# AIR32F103xx register map
File version: 1.3
Registers are 32-bit, read-write, reset 0x0 unless marked. A register's access mark holds for its fields unless they carry their own. Offsets are from the block's base; [hi:lo] are bit positions; {n}, {i} and the like mark numbered series.

## DBG — Debug support
Base 0xE0042000
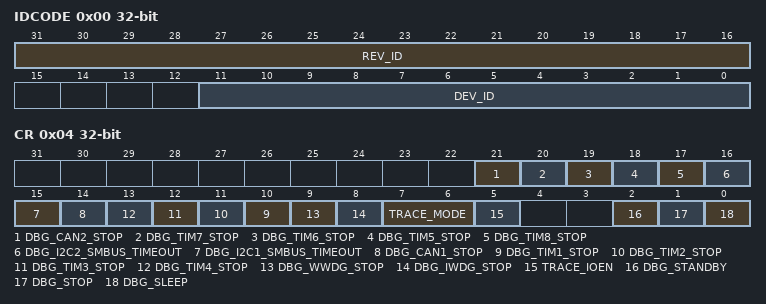
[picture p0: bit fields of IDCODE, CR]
0x00 IDCODE ro — DBGMCU_IDCODE
  [31:16] REV_ID, [11:0] DEV_ID
0x04 CR — DBGMCU_CR
  [21] DBG_CAN2_STOP, [20] DBG_TIM7_STOP, [19] DBG_TIM6_STOP, [18] DBG_TIM5_STOP, [17] DBG_TIM8_STOP, [16] DBG_I2C2_SMBUS_TIMEOUT, [15] DBG_I2C1_SMBUS_TIMEOUT, [14] DBG_CAN1_STOP, [n+9] DBG_TIM{n}_STOP (n=1..4), [9] DBG_WWDG_STOP, [8] DBG_IWDG_STOP, [7:6] TRACE_MODE, [5] TRACE_IOEN, [2] DBG_STANDBY, [1] DBG_STOP, [0] DBG_SLEEP

## UART4 — Universal asynchronous receiver transmitter
Base 0x40004C00
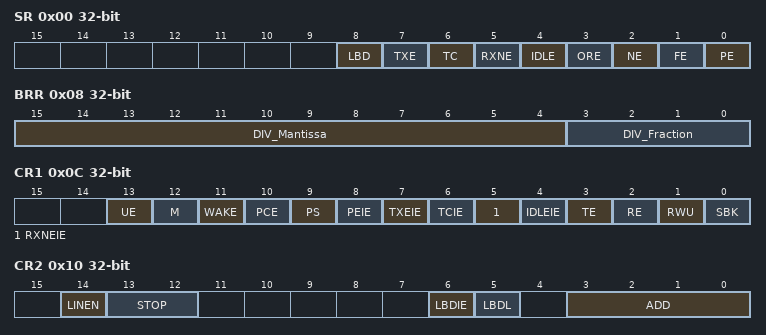
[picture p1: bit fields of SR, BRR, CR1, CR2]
0x00 SR access per field — UART4_SR
  [8] LBD rw — LIN break detection flag
  [7] TXE ro — Transmit data register empty
  [6] TC rw — Transmission complete
  [5] RXNE rw — Read data register not empty
  [4] IDLE ro — IDLE line detected
  [3] ORE ro — Overrun error
  [2] NE ro — Noise error flag
  [1] FE ro — Framing error
  [0] PE ro — Parity error
0x04 DR — UART4_DR
  [8:0] DR
0x08 BRR — UART4_BRR
  [15:4] DIV_Mantissa, [3:0] DIV_Fraction
0x0C CR1 — UART4_CR1
  [13] UE — USART enable
  [12] M — Word length
  [11] WAKE — Wakeup method
  [10] PCE — Parity control enable
  [9] PS — Parity selection
  [8] PEIE — PE interrupt enable
  [7] TXEIE — TXE interrupt enable
  [6] TCIE — Transmission complete interrupt enable
  [5] RXNEIE — RXNE interrupt enable
  [4] IDLEIE — IDLE interrupt enable
  [3] TE — Transmitter enable
  [2] RE — Receiver enable
  [1] RWU — Receiver wakeup
  [0] SBK — Send break
0x10 CR2 — UART4_CR2
  [14] LINEN — LIN mode enable
  [13:12] STOP — STOP bits
  [6] LBDIE — LIN break detection interrupt enable
  [5] LBDL — lin break detection length
  [3:0] ADD — Address of the USART node
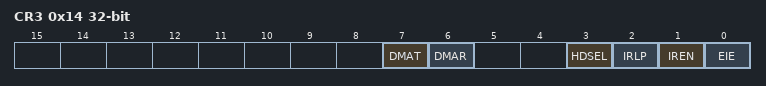
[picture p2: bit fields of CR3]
0x14 CR3 — UART4_CR3
  [7] DMAT — DMA enable transmitter
  [6] DMAR — DMA enable receiver
  [3] HDSEL — Half-duplex selection
  [2] IRLP — IrDA low-power
  [1] IREN — IrDA mode enable
  [0] EIE — Error interrupt enable

## UART5 — Universal asynchronous receiver transmitter
Base 0x40005000
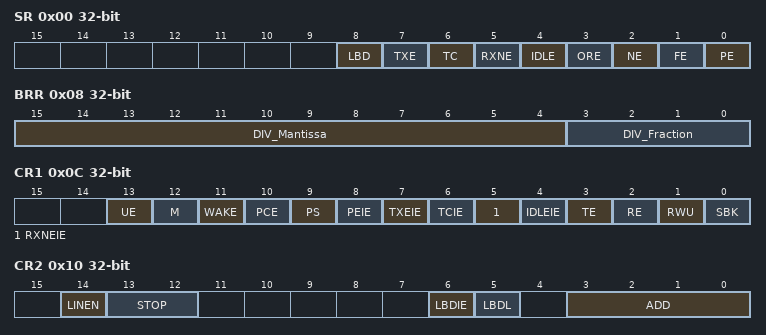
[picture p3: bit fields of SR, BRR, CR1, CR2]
0x00 SR access per field — UART4_SR
  [8] LBD rw, [7] TXE ro, [6] TC rw, [5] RXNE rw, [4] IDLE ro, [3] ORE ro, [2] NE ro, [1] FE ro, [0] PE ro
0x04 DR — UART4_DR
  [8:0] DR
0x08 BRR — UART4_BRR
  [15:4] DIV_Mantissa, [3:0] DIV_Fraction
0x0C CR1 — UART4_CR1
  [13] UE, [12] M, [11] WAKE, [10] PCE, [9] PS, [8] PEIE, [7] TXEIE, [6] TCIE, [5] RXNEIE, [4] IDLEIE, [3] TE, [2] RE, [1] RWU, [0] SBK
0x10 CR2 — UART4_CR2
  [14] LINEN, [13:12] STOP, [6] LBDIE, [5] LBDL, [3:0] ADD
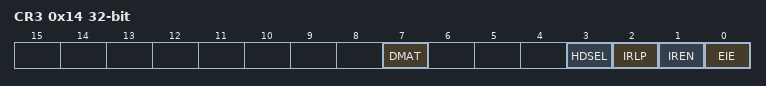
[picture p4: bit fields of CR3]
0x14 CR3 — UART4_CR3
  [7] DMAT — DMA enable transmitter
  [3] HDSEL — Half-duplex selection
  [2] IRLP — IrDA low-power
  [1] IREN — IrDA mode enable
  [0] EIE — Error interrupt enable

## CRC — CRC calculation unit
Base 0x40023000
0x00 DR reset 0xFFFFFFFF — Data register
  [31:0] DR — Data Register
0x04 IDR — Independent Data register
  [7:0] IDR
0x08 CR wo — Control register
  [0] RESET — Reset bit

## FLASH
Base 0x40022000
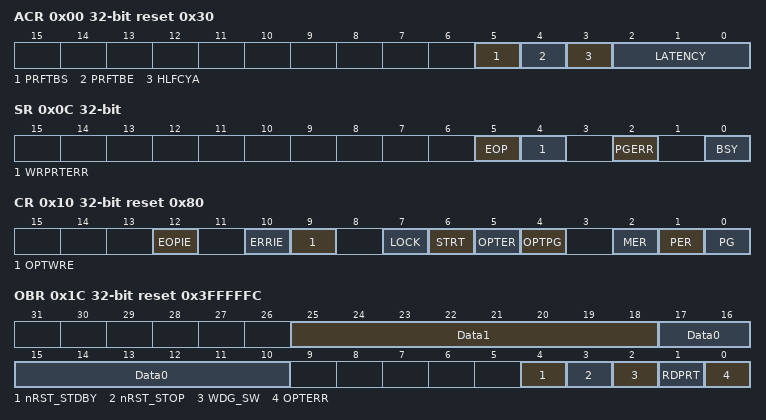
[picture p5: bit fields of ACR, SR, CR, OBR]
0x00 ACR access per field reset 0x30 — Flash access control register
  [5] PRFTBS ro — Prefetch buffer status
  [4] PRFTBE rw — Prefetch buffer enable
  [3] HLFCYA rw — Flash half cycle access enable
  [2:0] LATENCY rw
0x04 KEYR wo — Flash key register
  [31:0] KEY — FPEC key
0x08 OPTKEYR wo — Flash option key register
  [31:0] OPTKEY — Option byte key
0x0C SR access per field — Status register
  [5] EOP rw — End of operation
  [4] WRPRTERR rw — Write protection error
  [2] PGERR rw — Programming error
  [0] BSY ro — Busy
0x10 CR reset 0x80 — Control register
  [12] EOPIE — End of operation interrupt enable
  [10] ERRIE — Error interrupt enable
  [9] OPTWRE — Option bytes write enable
  [7] LOCK
  [6] STRT — Start
  [5] OPTER — Option byte erase
  [4] OPTPG — Option byte programming
  [2] MER — Mass Erase
  [1] PER — Page Erase
  [0] PG — Programming
0x14 AR wo — Flash address register
  [31:0] FAR — Flash Address
0x1C OBR ro reset 0x3FFFFFC — Option byte register
  [25:18] Data1
  [17:10] Data0
  [4] nRST_STDBY
  [3] nRST_STOP
  [2] WDG_SW
  [1] RDPRT — Read protection
  [0] OPTERR — Option byte error
0x20 WRPR ro reset 0xFFFFFFFF — Write protection register
  [31:0] WRP — Write protect

## NVIC — Nested Vectored Interrupt Controller
Base 0xE000E000
0x04 ICTR ro — Interrupt Controller Type Register
  [3:0] INTLINESNUM — Total number of interrupt lines in groups
0x100 ISER0 — Interrupt Set-Enable Register
  [31:0] SETENA
0x104 ISER1 — Interrupt Set-Enable Register
  [31:0] SETENA
0x180 ICER0 — Interrupt Clear-Enable Register
  [31:0] CLRENA
0x184 ICER1 — Interrupt Clear-Enable Register
  [31:0] CLRENA
0x200 ISPR0 — Interrupt Set-Pending Register
  [31:0] SETPEND
0x204 ISPR1 — Interrupt Set-Pending Register
  [31:0] SETPEND
0x280 ICPR0 — Interrupt Clear-Pending Register
  [31:0] CLRPEND
0x284 ICPR1 — Interrupt Clear-Pending Register
  [31:0] CLRPEND
0x300 IABR0 ro — Interrupt Active Bit Register
  [31:0] ACTIVE
0x304 IABR1 ro — Interrupt Active Bit Register
  [31:0] ACTIVE
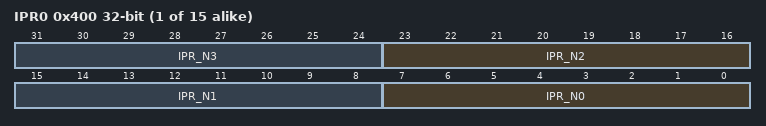
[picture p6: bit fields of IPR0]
{0x400+4i} IPR{i} (i=0..14) — Interrupt Priority Register
  [8n+7:8n] IPR_N{n} (n=0..3)
0xF00 STIR wo — Software Triggered Interrupt Register
  [8:0] INTID — interrupt to be triggered

## USB — Universal serial bus full-speed device interface
Base 0x40005C00
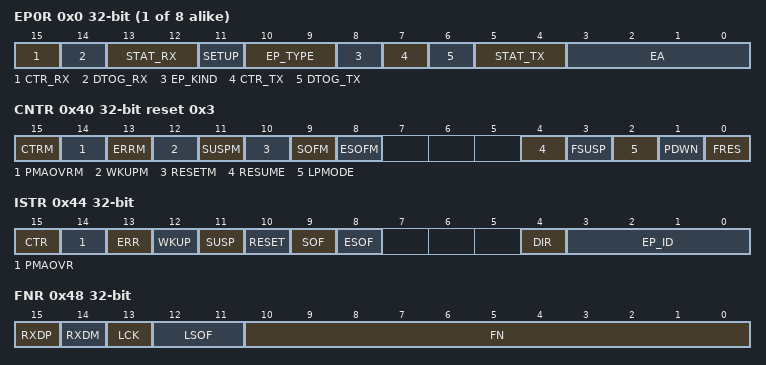
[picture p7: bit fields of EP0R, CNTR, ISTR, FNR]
{0x0+4i} EP{i}R (i=0..7) — endpoint {i} register
  [15] CTR_RX — Correct transfer for reception
  [14] DTOG_RX — Data Toggle, for reception transfers
  [13:12] STAT_RX — Status bits, for reception transfers
  [11] SETUP — Setup transaction completed
  [10:9] EP_TYPE — Endpoint type
  [8] EP_KIND — Endpoint kind
  [7] CTR_TX — Correct Transfer for transmission
  [6] DTOG_TX — Data Toggle, for transmission transfers
  [5:4] STAT_TX — Status bits, for transmission transfers
  [3:0] EA — Endpoint address
0x40 CNTR reset 0x3 — control register
  [15] CTRM — Correct transfer interrupt mask
  [14] PMAOVRM — Packet memory area over / underrun interrupt mask
  [13] ERRM — Error interrupt mask
  [12] WKUPM — Wakeup interrupt mask
  [11] SUSPM — Suspend mode interrupt mask
  [10] RESETM — USB reset interrupt mask
  [9] SOFM — Start of frame interrupt mask
  [8] ESOFM — Expected start of frame interrupt mask
  [4] RESUME — Resume request
  [3] FSUSP — Force suspend
  [2] LPMODE — Low-power mode
  [1] PDWN — Power down
  [0] FRES — Force USB Reset
0x44 ISTR — interrupt status register
  [15] CTR — Correct transfer
  [14] PMAOVR — Packet memory area over / underrun
  [13] ERR — Error
  [12] WKUP — Wakeup
  [11] SUSP — Suspend mode request
  [10] RESET — reset request
  [9] SOF — start of frame
  [8] ESOF — Expected start frame
  [4] DIR — Direction of transaction
  [3:0] EP_ID — Endpoint Identifier
0x48 FNR ro — frame number register
  [15] RXDP — Receive data + line status
  [14] RXDM — Receive data - line status
  [13] LCK — Locked
  [12:11] LSOF — Lost SOF
  [10:0] FN — Frame number
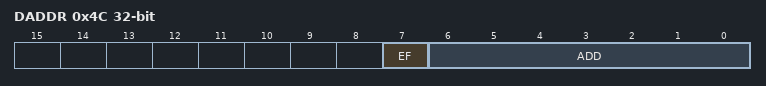
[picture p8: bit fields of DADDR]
0x4C DADDR — device address
  [7] EF — Enable function
  [6:0] ADD — Device address
0x50 BTABLE — Buffer table address
  [15:3] BTABLE — Buffer table
